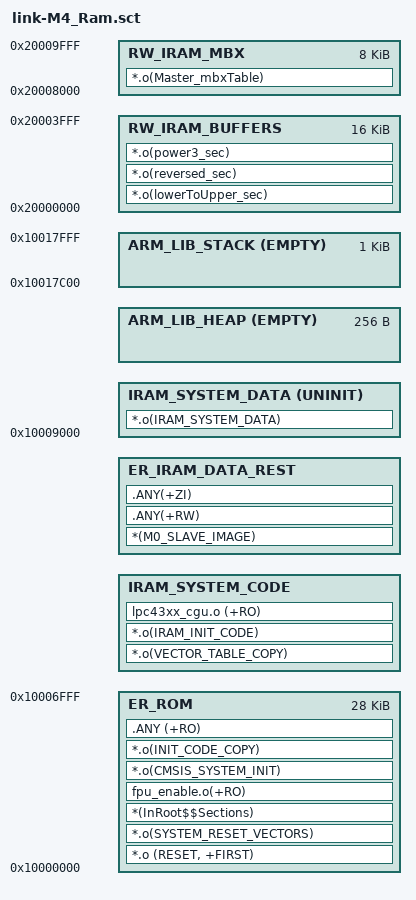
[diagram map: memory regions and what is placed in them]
; note: this scatter file is much more complicated than it could be
; this structure is kept for consistency with the flash and spifi versions
; for which the advanced scatter loading is used
LR_IRAM 0x10000000 0x18000  {    

  	; code
	ER_ROM 0x10000000 0x7000 {  
   		
		; vector table
		*.o (RESET, +FIRST)

		; system reset vectors
		*.o(SYSTEM_RESET_VECTORS) 
		 
	 	; used as an alias for the ARM library functions 
		; (__main, __scatter, __dc, __*region$$Table etc)
		*(InRoot$$Sections)	 
		
		; enable the fpu as soon as possible if present
		fpu_enable.o(+RO)
		
		; the cmsis system init function
		*.o(CMSIS_SYSTEM_INIT)

		; this code copies the initialization routines in ram
		; these are needed to change the PLL settings, the EMC settings	etc
		; are executed from IRAM_SYSTEM_CODE
		*.o(INIT_CODE_COPY)
				
		.ANY (+RO)
	}
	
	; these are the runtime locations for the initialization routines
	; which need to be executed from ram
	IRAM_SYSTEM_CODE +0 { 

		; routine for reallocating vector table (not used for ram project)
	   	*.o(VECTOR_TABLE_COPY)

	   	; platform initialization routines which need to run from ram
		*.o(IRAM_INIT_CODE)

		; cgu related functions
		lpc43xx_cgu.o (+RO)
		
	}

	ER_IRAM_DATA_REST +0 {

		; slave image
		*(M0_SLAVE_IMAGE)
	   
	   	; any other data
	   	.ANY(+RW)
	   	.ANY(+ZI)
	}

	; "SystemData_noInit" section  
	IRAM_SYSTEM_DATA 0x10009000 UNINIT {
  	
		*.o(IRAM_SYSTEM_DATA)
	}

	; setup a heap using default region name for arm lib "ARM_LIB_HEAP"
	ARM_LIB_HEAP +0 EMPTY 0x100 {  

	}

	; setup the stack using default region name for arm lib "ARM_LIB_STACK" 
	; is growing backwards so will overlap is no space is available
	ARM_LIB_STACK 0x10018000 EMPTY -0x400 {	 

	}

	RW_IRAM_BUFFERS 0x20000000 0x4000 { ; rw buffers
		*.o(lowerToUpper_sec)
		*.o(reversed_sec)
		*.o(power3_sec)  	
  	}
	
	; #define M4_MBX_START	0x20008000
	; #define M4_MBX_LEN		0x2000
	RW_IRAM_MBX 0x20008000 0x2000  {

		*.o(Master_mbxTable)
  } 
}






